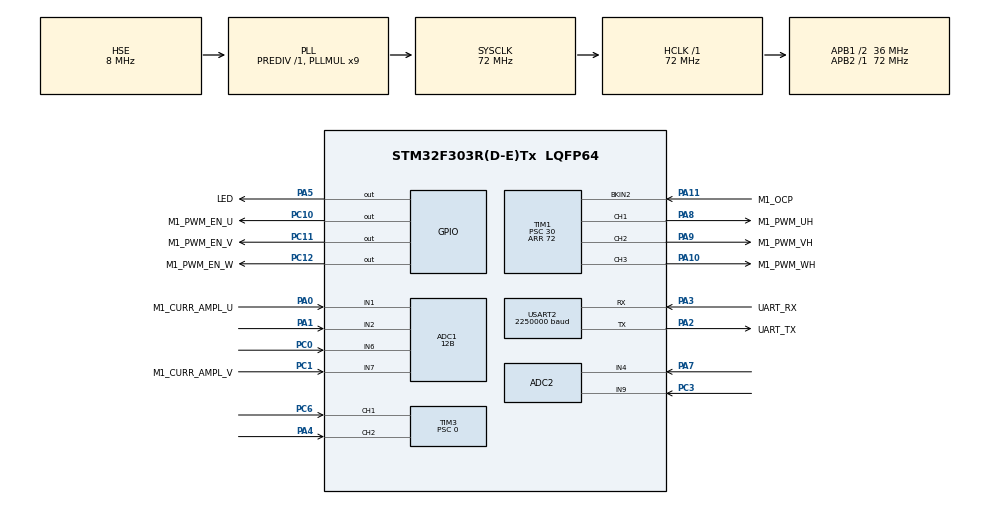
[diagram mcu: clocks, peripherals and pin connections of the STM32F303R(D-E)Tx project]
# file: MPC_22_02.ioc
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Dma.ADC2.2.Priority=DMA_PRIORITY_LOW
ADC1.LowPowerAutoWait=DISABLE
PC10.GPIO_PuPd=GPIO_PULLDOWN
TIM1.OCIdleState_1=TIM_OCIDLESTATE_RESET
TIM1.OCIdleState_2=TIM_OCIDLESTATE_RESET
Dma.USART2_TX.3.MemInc=DMA_MINC_ENABLE
PA10.GPIO_PuPd=GPIO_PULLDOWN
TIM1.Break2State=TIM_BREAK2_ENABLE
TIM1.OCIdleState_3=TIM_OCIDLESTATE_RESET
PC12.Signal=GPIO_Output
TIM1.OCIdleState_4=TIM_OCIDLESTATE_RESET
PA14.GPIO_Label=TCK
PA3.GPIO_PuPd=GPIO_NOPULL
ADC1.SamplingTimeOPAMP-4\#ChannelRegularConversion=ADC_SAMPLETIME_61CYCLES_5
PA3.GPIO_Speed=GPIO_SPEED_FREQ_LOW
TIM1.OCMode_PWM-PWM\ Generation3\ CH3=TIM_OCMODE_PWM1
Dma.USART2_RX.0.PeriphDataAlignment=DMA_PDATAALIGN_BYTE
RCC.APB2TimFreq_Value=72000000
ADC1.Channel-2\#ChannelRegularConversion=ADC_CHANNEL_7
Dma.ADC1.1.PeriphDataAlignment=DMA_PDATAALIGN_WORD
TIM1.AutomaticOutput=TIM_AUTOMATICOUTPUT_DISABLE
RCC.Usart2ClockSelection=RCC_USART2CLKSOURCE_SYSCLK
PC3.Signal=ADCx_IN9
ADC1.Offset-3\#ChannelRegularConversion=0
ADC1.ScanConvMode=ADC_SCAN_ENABLE
TIM1.LockLevel=TIM_LOCKLEVEL_1
USART2.OverSampling=UART_OVERSAMPLING_8
TIM1.Break2Polarity=TIM_BREAK2POLARITY_LOW
TIM1.Channel-PWM\ Generation1\ CH1=TIM_CHANNEL_1
PA0.Mode=IN1-Single-Ended
PC11.GPIO_Speed=GPIO_SPEED_FREQ_HIGH
PA8.Signal=S_TIM1_CH1
Dma.ADC2.2.Instance=DMA2_Channel1
VP_TIM1_VS_ClockSourceINT.Mode=Internal
PA0.Signal=ADC1_IN1
Mcu.Package=LQFP64
ADC1.EnableInjectedConversion=DISABLE
Dma.ADC2.2.PeriphInc=DMA_PINC_DISABLE
ADC2.Channel-20\#ChannelRegularConversion=ADC_CHANNEL_9
TIM1.OCFastMode_PWM-PWM\ Generation3\ CH3=TIM_OCFAST_ENABLE
PA10.Signal=S_TIM1_CH3
PC6.GPIO_PuPd=GPIO_PULLUP
SH.ADCx_IN9.0=ADC2_IN9,IN9-Single-Ended
Dma.ADC2.2.MemInc=DMA_MINC_ENABLE
RCC.APB1TimFreq_Value=72000000
TIM1.Period=72
PC12.GPIO_PuPd=GPIO_PULLDOWN
Dma.ADC2.2.PeriphDataAlignment=DMA_PDATAALIGN_WORD
TIM1.OCFastMode_PWM-PWM\ Generation4\ No\ Output=TIM_OCFAST_ENABLE
PA8.GPIO_Speed=GPIO_SPEED_FREQ_HIGH
ADC1.EOCSelection=ADC_EOC_SINGLE_CONV
PF1-OSC_OUT.Signal=RCC_OSC_OUT
ADC1.Rank-4\#ChannelRegularConversion=4
PA2.GPIO_Mode=GPIO_MODE_AF_PP
NVIC.DMA1_Channel6_IRQn=true\:1\:0\:true\:true\:true\:2\:true\:true
TIM1.OCPolarity_1=TIM_OCPOLARITY_HIGH
TIM1.OCPolarity_3=TIM_OCPOLARITY_HIGH
TIM1.OCPolarity_2=TIM_OCPOLARITY_HIGH
TIM1.OCPolarity_4=TIM_OCPOLARITY_HIGH
TIM3.AutoReloadPreload=TIM_AUTORELOAD_PRELOAD_ENABLE
SH.ADCx_IN6.0=ADC1_IN6,IN6-Single-Ended
TIM1.CounterMode=TIM_COUNTERMODE_CENTERALIGNED1
PA9.GPIO_Label=M1_PWM_VH
PC6.Signal=S_TIM3_CH1
Dma.USART2_RX.0.Direction=DMA_PERIPH_TO_MEMORY
PA11.GPIO_Label=M1_OCP
Dma.USART2_TX.3.PeriphInc=DMA_PINC_DISABLE
ADC1.ExternalTrigConvEdge=ADC_EXTERNALTRIGCONVEDGE_NONE
PC0.Signal=ADCx_IN6
RCC.APB1CLKDivider=RCC_HCLK_DIV2
USART2.BaudRate=2250000
TIM1.AutoReloadPreload=TIM_AUTORELOAD_PRELOAD_ENABLE
PA3.Mode=Asynchronous
TIM1.BreakFilter=0
PA8.GPIO_Label=M1_PWM_UH
ADC2.OffsetNumber-19\#ChannelRegularConversion=ADC_OFFSET_NONE
ADC2.ContinuousConvMode=ENABLE
SH.ADCx_IN7.0=ADC1_IN7,IN7-Single-Ended
PA9.Signal=S_TIM1_CH2
TIM1.Channel-PWM\ Generation2\ CH2=TIM_CHANNEL_2
USART2.OneBitSampling=UART_ONE_BIT_SAMPLE_ENABLE
ADC1.Offset-2\#ChannelRegularConversion=0
PA5.Signal=GPIO_Output
RCC.TIM8Selection=RCC_TIM8CLK_PLLCLK
NVIC.TIM1_BRK_TIM15_IRQn=true\:0\:0\:false\:false\:true\:true\:true
TIM1.TIM_MasterOutputTrigger=TIM_TRGO_OC4REF
PA1.Mode=IN2-Single-Ended
PA4.GPIO_ModeDefaultPP=GPIO_MODE_AF_PP
Dma.USART2_TX.3.Mode=DMA_NORMAL
Dma.ADC2.2.Direction=DMA_PERIPH_TO_MEMORY
ADC2.Rank-19\#ChannelRegularConversion=1
ADC1.DMAContinuousRequests=DISABLE
PA13.Mode=Serial_Wire
TIM1.Channel-PWM\ Generation4\ No\ Output=TIM_CHANNEL_4
Dma.USART2_RX.0.MemInc=DMA_MINC_ENABLE
ADC1.ExternalTrigConv=ADC_SOFTWARE_START
NVIC.TIM1_CC_IRQn=true\:0\:0\:false\:true\:true\:1\:true\:true
Dma.ADC2.2.Mode=DMA_CIRCULAR
ADC1.SamplingTime-1\#ChannelRegularConversion=ADC_SAMPLETIME_1CYCLE_5
PA4.Signal=S_TIM3_CH2
ADC1.master=1
ADC2.Channel-19\#ChannelRegularConversion=ADC_CHANNEL_4
ADC2.NbrOfConversionFlag=1
PA5.GPIO_Label=LED
PC12.GPIO_Label=M1_PWM_EN_W
ADC1.Rank-1\#ChannelRegularConversion=1
PA11.Signal=TIM1_BKIN2
ProjectManager.HeapSize=0x200
Dma.USART2_TX.3.Priority=DMA_PRIORITY_LOW
NVIC.PriorityGroup=NVIC_PRIORITYGROUP_3
ADC1.EnableRegularConversion=ENABLE
TIM1.Channel-PWM\ Generation3\ CH3=TIM_CHANNEL_3
PF0-OSC_IN.Signal=RCC_OSC_IN
PC1.Signal=ADCx_IN7
RCC.TIM2Selection=RCC_TIM2CLK_PLLCLK
Mcu.Family=STM32F3
PA2.GPIO_PuPd=GPIO_NOPULL
RCC.CortexFreq_Value=72000000
Dma.ADC1.1.MemDataAlignment=DMA_MDATAALIGN_WORD
ADC1.Overrun=ADC_OVR_DATA_OVERWRITTEN
ADC1.ContinuousConvMode=ENABLE
TIM1.RepetitionCounter=0
PC10.Signal=GPIO_Output
RCC.SYSCLKSourceVirtual=RCC_SYSCLKSOURCE_PLLCLK
ADC1.OffsetNumber-4\#ChannelRegularConversion=ADC_OFFSET_NONE
PA0.GPIO_Label=M1_CURR_AMPL_U
TIM3.EncoderMode=TIM_ENCODERMODE_TI1
PA2.GPIO_Speed=GPIO_SPEED_FREQ_LOW
PA11.Mode=Activate-Break-Input-2
PC10.GPIO_Speed=GPIO_SPEED_FREQ_HIGH
PA11.GPIO_PuPd=GPIO_PULLUP
Dma.USART2_TX.3.Direction=DMA_MEMORY_TO_PERIPH
TIM1.Pulse-PWM\ Generation1\ CH1=0
TIM1.OCFastMode_PWM-PWM\ Generation1\ CH1=TIM_OCFAST_ENABLE
ProjectManager.StackSize=0x400
PC11.GPIO_PuPd=GPIO_PULLDOWN
TIM1.Prescaler=30
Dma.USART2_RX.0.Priority=DMA_PRIORITY_LOW
Dma.ADC1.1.Instance=DMA1_Channel1
PC6.GPIO_ModeDefaultPP=GPIO_MODE_AF_PP
ADC1.Channel-3\#ChannelRegularConversion=ADC_CHANNEL_6
RCC.HCLKFreq_Value=72000000
ADC1.Resolution=ADC_RESOLUTION_12B
ADC1.Offset-1\#ChannelRegularConversion=0
TIM3.Period=599
ADC2.Offset-20\#ChannelRegularConversion=0
RCC.AHBFreq_Value=72000000
RCC.HSE_VALUE=8000000
PA4.GPIO_PuPd=GPIO_PULLUP
USART2.VirtualMode-Asynchronous=VM_ASYNC
RCC.PLLMUL=RCC_PLL_MUL9
ADC1.SamplingTime-4\#ChannelRegularConversion=ADC_SAMPLETIME_1CYCLE_5
ADC1.Rank-2\#ChannelRegularConversion=2
Dma.USART2_RX.0.MemDataAlignment=DMA_MDATAALIGN_BYTE
ADC2.SamplingTime-20\#ChannelRegularConversion=ADC_SAMPLETIME_1CYCLE_5
PA14.Mode=Serial_Wire
TIM3.Prescaler=0
PC11.GPIO_Label=M1_PWM_EN_V
PA10.GPIO_Label=M1_PWM_WH
Dma.USART2_RX.0.Instance=DMA1_Channel6
Dma.ADC1.1.Priority=DMA_PRIORITY_LOW
Dma.ADC1.1.Mode=DMA_CIRCULAR
ADC2.Offset-19\#ChannelRegularConversion=0
SH.S_TIM3_CH1.0=TIM3_CH1,Encoder_Interface
Dma.USART2_RX.0.PeriphInc=DMA_PINC_DISABLE
TIM1.Pulse-PWM\ Generation2\ CH2=0
Dma.ADC1.1.Direction=DMA_PERIPH_TO_MEMORY
Dma.ADC2.2.MemDataAlignment=DMA_MDATAALIGN_WORD
ADC2.OffsetNumber-20\#ChannelRegularConversion=ADC_OFFSET_NONE
PA2.GPIO_Label=UART_TX
Dma.ADC1.1.MemInc=DMA_MINC_ENABLE
ADC1.OffsetNumber-1\#ChannelRegularConversion=ADC_OFFSET_NONE
USART2.WordLength=WORDLENGTH_8B
PA10.GPIO_Speed=GPIO_SPEED_FREQ_HIGH
ADC2.NbrOfConversion=2
TIM1.BreakState=TIM_BREAK_DISABLE
Dma.Request2=ADC2
Dma.Request1=ADC1
Dma.Request3=USART2_TX
PF1-OSC_OUT.Mode=HSE-External-Oscillator
Dma.Request0=USART2_RX
PA3.Signal=USART2_RX
RCC.PLLSourceVirtual=RCC_PLLSOURCE_HSE
Dma.USART2_TX.3.MemDataAlignment=DMA_MDATAALIGN_BYTE
TIM1.OCMode_PWM-PWM\ Generation4\ No\ Output=TIM_OCMODE_PWM2
TIM1.OffStateIDLEMode=TIM_OSSI_ENABLE
PA7.Mode=IN4-Single-Ended
ADC1.Channel-4\#ChannelRegularConversion=ADC_CHANNEL_2
USART2.DMADisableonRxErrorParam=ADVFEATURE_DMA_DISABLEONRXERROR
PC10.GPIO_Label=M1_PWM_EN_U
Dma.USART2_TX.3.Instance=DMA1_Channel7
PC11.Signal=GPIO_Output
ADC1.OffsetNumber-3\#ChannelRegularConversion=ADC_OFFSET_NONE
ADC1.DiscontinuousConvMode=DISABLE
PA9.GPIO_PuPd=GPIO_PULLDOWN
ADC1.SamplingTime-2\#ChannelRegularConversion=ADC_SAMPLETIME_1CYCLE_5
TIM1.ClockDivision=TIM_CLOCKDIVISION_DIV1
Dma.USART2_RX.0.Mode=DMA_CIRCULAR
TIM1.ClearInputSource=TIM_CLEARINPUTSOURCE_NONE
TIM1.OCFastMode_PWM-PWM\ Generation2\ CH2=TIM_OCFAST_ENABLE
PA13.Signal=SYS_JTMS-SWDIO
TIM1.Pulse-PWM\ Generation3\ CH3=0
SH.S_TIM1_CH1.0=TIM1_CH1,PWM Generation1 CH1
ProjectManager.TargetToolchain=STM32CubeIDE
PA3.GPIO_Mode=GPIO_MODE_AF_PP
ADC1.Channel-1\#ChannelRegularConversion=ADC_CHANNEL_1
ADC1.EnableAnalogWatchDog3=false
ADC1.EnableAnalogWatchDog2=false
ADC1.EnableAnalogWatchDog1=false
Dma.USART2_TX.3.PeriphDataAlignment=DMA_PDATAALIGN_BYTE
RCC.USBFreq_Value=72000000
RCC.LSE_VALUE=32768
PA1.Signal=ADC1_IN2
ADC1.Offset-4\#ChannelRegularConversion=0
PF0-OSC_IN.Mode=HSE-External-Oscillator
TIM3.IC2Polarity=TIM_ICPOLARITY_FALLING
ADC2.SamplingTime-19\#ChannelRegularConversion=ADC_SAMPLETIME_1CYCLE_5
SH.S_TIM3_CH2.0=TIM3_CH2,Encoder_Interface
board=custom
VP_TIM1_VS_no_output4.Mode=PWM Generation4 No Output
TIM1.Pulse-PWM\ Generation4\ No\ Output=72
RCC.APB2Freq_Value=72000000
SH.S_TIM1_CH2.0=TIM1_CH2,PWM Generation2 CH2
PC1.GPIO_Label=M1_CURR_AMPL_V
ADC2.Rank-20\#ChannelRegularConversion=2
Dma.ADC1.1.PeriphInc=DMA_PINC_DISABLE
TIM1.OffStateRunMode=TIM_OSSR_ENABLE
TIM1.BreakPolarity=TIM_BREAKPOLARITY_HIGH
ADC1.NbrOfConversion=4
ADC1.OffsetNumber-2\#ChannelRegularConversion=ADC_OFFSET_NONE
Mcu.Name=STM32F303R(D-E)Tx
TIM1.OCMode_PWM-PWM\ Generation1\ CH1=TIM_OCMODE_PWM1
PA13.GPIO_Label=TMS
PA2.Signal=USART2_TX
RCC.SYSCLKFreq_VALUE=72000000
TIM1.TIM_MasterOutputTrigger2=TIM_TRGO2_UPDATE
ADC1.SamplingTime-3\#ChannelRegularConversion=ADC_SAMPLETIME_1CYCLE_5
ADC1.Rank-3\#ChannelRegularConversion=3
TIM1.Break2Filter=3
TIM3.IC1Polarity=TIM_ICPOLARITY_FALLING
PA14.Signal=SYS_JTCK-SWCLK
SH.S_TIM1_CH3.0=TIM1_CH3,PWM Generation3 CH3
RCC.HSI_VALUE=8000000
PA8.GPIO_PuPd=GPIO_PULLDOWN
PA5.GPIO_Speed=GPIO_SPEED_FREQ_HIGH
ADC1.NbrOfConversionFlag=1
TIM1.OCMode_PWM-PWM\ Generation2\ CH2=TIM_OCMODE_PWM1
PA2.Mode=Asynchronous
PA9.GPIO_Speed=GPIO_SPEED_FREQ_HIGH
TIM3.TIM_MasterOutputTrigger=TIM_TRGO_RESET
ADC1.DataAlign=ADC_DATAALIGN_RIGHT
RCC.APB1Freq_Value=36000000
PC12.GPIO_Speed=GPIO_SPEED_FREQ_HIGH
TIM1.TIM_MasterSlaveMode=TIM_MASTERSLAVEMODE_DISABLE
PA3.GPIO_Label=UART_RX
PA7.Signal=ADC2_IN4

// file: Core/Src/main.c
/* USER CODE BEGIN Header */
/**
  ******************************************************************************
  * @file           : main.c
  * @brief          : Main program body
  ******************************************************************************
  * @attention
  *
  * <h2><center>&copy; Copyright (c) 2022 STMicroelectronics.
  * All rights reserved.</center></h2>
  *
  * This software component is licensed by ST under BSD 3-Clause license,
  * the "License"; You may not use this file except in compliance with the
  * License. You may obtain a copy of the License at:
  *                        opensource.org/licenses/BSD-3-Clause
  *
  ******************************************************************************
  */
/* USER CODE END Header */
#include "main.h"

/* USER CODE BEGIN PD */
void receiveUART();
void initModelPredictiveControl();
/* USER CODE END PD */

ADC_HandleTypeDef hadc1;
ADC_HandleTypeDef hadc2;
DMA_HandleTypeDef hdma_adc1;
DMA_HandleTypeDef hdma_adc2;

TIM_HandleTypeDef htim1;
TIM_HandleTypeDef htim3;

UART_HandleTypeDef huart2;
DMA_HandleTypeDef hdma_usart2_rx;
DMA_HandleTypeDef hdma_usart2_tx;

void SystemClock_Config(void);
static void MX_GPIO_Init(void);
static void MX_DMA_Init(void);
static void MX_ADC1_Init(void);
static void MX_TIM1_Init(void);
static void MX_USART2_UART_Init(void);
static void MX_ADC2_Init(void);
static void MX_TIM3_Init(void);
static void MX_NVIC_Init(void);

int main(void)
{

  /* MCU Configuration--------------------------------------------------------*/

  /* Reset of all peripherals, Initializes the Flash interface and the Systick. */
  HAL_Init();

  /* Configure the system clock */
  SystemClock_Config();

  /* Initialize all configured peripherals */
  MX_GPIO_Init();
  MX_DMA_Init();
  MX_ADC1_Init();
  MX_TIM1_Init();
  MX_USART2_UART_Init();
  MX_ADC2_Init();
  MX_TIM3_Init();

  /* Initialize interrupts */
  MX_NVIC_Init();
  /* USER CODE BEGIN 2 */
	HAL_TIM_Encoder_Start(&htim3, TIM_CHANNEL_ALL);

	initModelPredictiveControl();

	// Calibrate ADCs
		HAL_ADCEx_Calibration_Start(&hadc1, ADC_SINGLE_ENDED);

		// Enable MOSFET drivers
		HAL_GPIO_WritePin(GPIOC, GPIO_PIN_10, 1);
		HAL_GPIO_WritePin(GPIOC, GPIO_PIN_11, 1);
		HAL_GPIO_WritePin(GPIOC, GPIO_PIN_12, 1);

	//	 Start timers
		HAL_TIM_PWM_Start_IT(&htim1, TIM_CHANNEL_4);
		HAL_TIM_PWM_Start(&htim1, TIM_CHANNEL_1);
		HAL_TIM_PWM_Start(&htim1, TIM_CHANNEL_2);
		HAL_TIM_PWM_Start(&htim1, TIM_CHANNEL_3);

		receiveUART();

  /* USER CODE END 2 */

  /* Infinite loop */
  while (1)
  {

  }
}

void SystemClock_Config(void)
{
  RCC_OscInitTypeDef RCC_OscInitStruct = {0};
  RCC_ClkInitTypeDef RCC_ClkInitStruct = {0};
  RCC_PeriphCLKInitTypeDef PeriphClkInit = {0};

  /** Initializes the RCC Oscillators according to the specified parameters
  * in the RCC_OscInitTypeDef structure.
  */
  RCC_OscInitStruct.OscillatorType = RCC_OSCILLATORTYPE_HSE;
  RCC_OscInitStruct.HSEState = RCC_HSE_ON;
  RCC_OscInitStruct.HSIState = RCC_HSI_ON;
  RCC_OscInitStruct.PLL.PLLState = RCC_PLL_ON;
  RCC_OscInitStruct.PLL.PLLSource = RCC_PLLSOURCE_HSE;
  RCC_OscInitStruct.PLL.PLLMUL = RCC_PLL_MUL9;
  RCC_OscInitStruct.PLL.PREDIV = RCC_PREDIV_DIV1;
  if (HAL_RCC_OscConfig(&RCC_OscInitStruct) != HAL_OK)
  {
    Error_Handler();
  }
  /** Initializes the CPU, AHB and APB buses clocks
  */
  RCC_ClkInitStruct.ClockType = RCC_CLOCKTYPE_HCLK|RCC_CLOCKTYPE_SYSCLK
                              |RCC_CLOCKTYPE_PCLK1|RCC_CLOCKTYPE_PCLK2;
  RCC_ClkInitStruct.SYSCLKSource = RCC_SYSCLKSOURCE_PLLCLK;
  RCC_ClkInitStruct.AHBCLKDivider = RCC_SYSCLK_DIV1;
  RCC_ClkInitStruct.APB1CLKDivider = RCC_HCLK_DIV2;
  RCC_ClkInitStruct.APB2CLKDivider = RCC_HCLK_DIV1;

  if (HAL_RCC_ClockConfig(&RCC_ClkInitStruct, FLASH_LATENCY_2) != HAL_OK)
  {
    Error_Handler();
  }
  PeriphClkInit.PeriphClockSelection = RCC_PERIPHCLK_USART2|RCC_PERIPHCLK_TIM1
                              |RCC_PERIPHCLK_ADC12|RCC_PERIPHCLK_TIM34;
  PeriphClkInit.Usart2ClockSelection = RCC_USART2CLKSOURCE_SYSCLK;
  PeriphClkInit.Adc12ClockSelection = RCC_ADC12PLLCLK_DIV1;
  PeriphClkInit.Tim1ClockSelection = RCC_TIM1CLK_HCLK;
  PeriphClkInit.Tim34ClockSelection = RCC_TIM34CLK_HCLK;
  if (HAL_RCCEx_PeriphCLKConfig(&PeriphClkInit) != HAL_OK)
  {
    Error_Handler();
  }
}

/**
  * @brief NVIC Configuration.
  * @retval None
  */
static void MX_NVIC_Init(void)
{
  /* TIM1_CC_IRQn interrupt configuration */
  HAL_NVIC_SetPriority(TIM1_CC_IRQn, 0, 0);
  HAL_NVIC_EnableIRQ(TIM1_CC_IRQn);
  /* DMA1_Channel6_IRQn interrupt configuration */
  HAL_NVIC_SetPriority(DMA1_Channel6_IRQn, 1, 0);
  HAL_NVIC_EnableIRQ(DMA1_Channel6_IRQn);
}

static void MX_ADC1_Init(void)
{

  ADC_MultiModeTypeDef multimode = {0};
  ADC_ChannelConfTypeDef sConfig = {0};

  /** Common config
  */
  hadc1.Instance = ADC1;
  hadc1.Init.ClockPrescaler = ADC_CLOCK_ASYNC_DIV1;
  hadc1.Init.Resolution = ADC_RESOLUTION_12B;
  hadc1.Init.ScanConvMode = ADC_SCAN_ENABLE;
  hadc1.Init.ContinuousConvMode = ENABLE;
  hadc1.Init.DiscontinuousConvMode = DISABLE;
  hadc1.Init.ExternalTrigConvEdge = ADC_EXTERNALTRIGCONVEDGE_NONE;
  hadc1.Init.ExternalTrigConv = ADC_SOFTWARE_START;
  hadc1.Init.DataAlign = ADC_DATAALIGN_RIGHT;
  hadc1.Init.NbrOfConversion = 4;
  hadc1.Init.DMAContinuousRequests = DISABLE;
  hadc1.Init.EOCSelection = ADC_EOC_SINGLE_CONV;
  hadc1.Init.LowPowerAutoWait = DISABLE;
  hadc1.Init.Overrun = ADC_OVR_DATA_OVERWRITTEN;
  if (HAL_ADC_Init(&hadc1) != HAL_OK)
  {
    Error_Handler();
  }
  /** Configure the ADC multi-mode
  */
  multimode.Mode = ADC_MODE_INDEPENDENT;
  if (HAL_ADCEx_MultiModeConfigChannel(&hadc1, &multimode) != HAL_OK)
  {
    Error_Handler();
  }
  /** Configure Regular Channel
  */
  sConfig.Channel = ADC_CHANNEL_1;
  sConfig.Rank = ADC_REGULAR_RANK_1;
  sConfig.SingleDiff = ADC_SINGLE_ENDED;
  sConfig.SamplingTime = ADC_SAMPLETIME_1CYCLE_5;
  sConfig.OffsetNumber = ADC_OFFSET_NONE;
  sConfig.Offset = 0;
  if (HAL_ADC_ConfigChannel(&hadc1, &sConfig) != HAL_OK)
  {
    Error_Handler();
  }
  /** Configure Regular Channel
  */
  sConfig.Channel = ADC_CHANNEL_7;
  sConfig.Rank = ADC_REGULAR_RANK_2;
  if (HAL_ADC_ConfigChannel(&hadc1, &sConfig) != HAL_OK)
  {
    Error_Handler();
  }
  /** Configure Regular Channel
  */
  sConfig.Channel = ADC_CHANNEL_6;
  sConfig.Rank = ADC_REGULAR_RANK_3;
  if (HAL_ADC_ConfigChannel(&hadc1, &sConfig) != HAL_OK)
  {
    Error_Handler();
  }
  /** Configure Regular Channel
  */
  sConfig.Channel = ADC_CHANNEL_2;
  sConfig.Rank = ADC_REGULAR_RANK_4;
  if (HAL_ADC_ConfigChannel(&hadc1, &sConfig) != HAL_OK)
  {
    Error_Handler();
  }

}

static void MX_ADC2_Init(void)
{

  ADC_ChannelConfTypeDef sConfig = {0};

  /** Common config
  */
  hadc2.Instance = ADC2;
  hadc2.Init.ClockPrescaler = ADC_CLOCK_ASYNC_DIV1;
  hadc2.Init.Resolution = ADC_RESOLUTION_12B;
  hadc2.Init.ScanConvMode = ADC_SCAN_ENABLE;
  hadc2.Init.ContinuousConvMode = ENABLE;
  hadc2.Init.DiscontinuousConvMode = DISABLE;
  hadc2.Init.ExternalTrigConvEdge = ADC_EXTERNALTRIGCONVEDGE_NONE;
  hadc2.Init.ExternalTrigConv = ADC_SOFTWARE_START;
  hadc2.Init.DataAlign = ADC_DATAALIGN_RIGHT;
  hadc2.Init.NbrOfConversion = 2;
  hadc2.Init.DMAContinuousRequests = DISABLE;
  hadc2.Init.EOCSelection = ADC_EOC_SINGLE_CONV;
  hadc2.Init.LowPowerAutoWait = DISABLE;
  hadc2.Init.Overrun = ADC_OVR_DATA_OVERWRITTEN;
  if (HAL_ADC_Init(&hadc2) != HAL_OK)
  {
    Error_Handler();
  }
  /** Configure Regular Channel
  */
  sConfig.Channel = ADC_CHANNEL_4;
  sConfig.Rank = ADC_REGULAR_RANK_1;
  sConfig.SingleDiff = ADC_SINGLE_ENDED;
  sConfig.SamplingTime = ADC_SAMPLETIME_1CYCLE_5;
  sConfig.OffsetNumber = ADC_OFFSET_NONE;
  sConfig.Offset = 0;
  if (HAL_ADC_ConfigChannel(&hadc2, &sConfig) != HAL_OK)
  {
    Error_Handler();
  }
  /** Configure Regular Channel
  */
  sConfig.Channel = ADC_CHANNEL_9;
  sConfig.Rank = ADC_REGULAR_RANK_2;
  if (HAL_ADC_ConfigChannel(&hadc2, &sConfig) != HAL_OK)
  {
    Error_Handler();
  }

}

static void MX_TIM1_Init(void)
{

  TIM_ClockConfigTypeDef sClockSourceConfig = {0};
  TIM_MasterConfigTypeDef sMasterConfig = {0};
  TIM_OC_InitTypeDef sConfigOC = {0};
  TIM_BreakDeadTimeConfigTypeDef sBreakDeadTimeConfig = {0};

  htim1.Instance = TIM1;
  htim1.Init.Prescaler = 30;
  htim1.Init.CounterMode = TIM_COUNTERMODE_CENTERALIGNED1;
  htim1.Init.Period = 72;
  htim1.Init.ClockDivision = TIM_CLOCKDIVISION_DIV1;
  htim1.Init.RepetitionCounter = 0;
  htim1.Init.AutoReloadPreload = TIM_AUTORELOAD_PRELOAD_ENABLE;
  if (HAL_TIM_Base_Init(&htim1) != HAL_OK)
  {
    Error_Handler();
  }
  sClockSourceConfig.ClockSource = TIM_CLOCKSOURCE_INTERNAL;
  if (HAL_TIM_ConfigClockSource(&htim1, &sClockSourceConfig) != HAL_OK)
  {
    Error_Handler();
  }
  if (HAL_TIM_PWM_Init(&htim1) != HAL_OK)
  {
    Error_Handler();
  }
  sMasterConfig.MasterOutputTrigger = TIM_TRGO_OC4REF;
  sMasterConfig.MasterOutputTrigger2 = TIM_TRGO2_UPDATE;
  sMasterConfig.MasterSlaveMode = TIM_MASTERSLAVEMODE_DISABLE;
  if (HAL_TIMEx_MasterConfigSynchronization(&htim1, &sMasterConfig) != HAL_OK)
  {
    Error_Handler();
  }
  sConfigOC.OCMode = TIM_OCMODE_PWM1;
  sConfigOC.Pulse = 0;
  sConfigOC.OCPolarity = TIM_OCPOLARITY_HIGH;
  sConfigOC.OCNPolarity = TIM_OCNPOLARITY_HIGH;
  sConfigOC.OCFastMode = TIM_OCFAST_ENABLE;
  sConfigOC.OCIdleState = TIM_OCIDLESTATE_RESET;
  sConfigOC.OCNIdleState = TIM_OCNIDLESTATE_RESET;
  if (HAL_TIM_PWM_ConfigChannel(&htim1, &sConfigOC, TIM_CHANNEL_1) != HAL_OK)
  {
    Error_Handler();
  }
  if (HAL_TIM_PWM_ConfigChannel(&htim1, &sConfigOC, TIM_CHANNEL_2) != HAL_OK)
  {
    Error_Handler();
  }
  if (HAL_TIM_PWM_ConfigChannel(&htim1, &sConfigOC, TIM_CHANNEL_3) != HAL_OK)
  {
    Error_Handler();
  }
  sConfigOC.OCMode = TIM_OCMODE_PWM2;
  sConfigOC.Pulse = 72;
  if (HAL_TIM_PWM_ConfigChannel(&htim1, &sConfigOC, TIM_CHANNEL_4) != HAL_OK)
  {
    Error_Handler();
  }
  sBreakDeadTimeConfig.OffStateRunMode = TIM_OSSR_ENABLE;
  sBreakDeadTimeConfig.OffStateIDLEMode = TIM_OSSI_ENABLE;
  sBreakDeadTimeConfig.LockLevel = TIM_LOCKLEVEL_1;
  sBreakDeadTimeConfig.DeadTime = 0;
  sBreakDeadTimeConfig.BreakState = TIM_BREAK_DISABLE;
  sBreakDeadTimeConfig.BreakPolarity = TIM_BREAKPOLARITY_HIGH;
  sBreakDeadTimeConfig.BreakFilter = 0;
  sBreakDeadTimeConfig.Break2State = TIM_BREAK2_ENABLE;
  sBreakDeadTimeConfig.Break2Polarity = TIM_BREAK2POLARITY_LOW;
  sBreakDeadTimeConfig.Break2Filter = 3;
  sBreakDeadTimeConfig.AutomaticOutput = TIM_AUTOMATICOUTPUT_DISABLE;
  if (HAL_TIMEx_ConfigBreakDeadTime(&htim1, &sBreakDeadTimeConfig) != HAL_OK)
  {
    Error_Handler();
  }
  HAL_TIM_MspPostInit(&htim1);

}

static void MX_TIM3_Init(void)
{

  TIM_Encoder_InitTypeDef sConfig = {0};
  TIM_MasterConfigTypeDef sMasterConfig = {0};

  htim3.Instance = TIM3;
  htim3.Init.Prescaler = 0;
  htim3.Init.CounterMode = TIM_COUNTERMODE_UP;
  htim3.Init.Period = 299;
  htim3.Init.ClockDivision = TIM_CLOCKDIVISION_DIV1;
  htim3.Init.AutoReloadPreload = TIM_AUTORELOAD_PRELOAD_ENABLE;
  sConfig.EncoderMode = TIM_ENCODERMODE_TI1;
  sConfig.IC1Polarity = TIM_ICPOLARITY_FALLING;
  sConfig.IC1Selection = TIM_ICSELECTION_DIRECTTI;
  sConfig.IC1Prescaler = TIM_ICPSC_DIV1;
  sConfig.IC1Filter = 0;
  sConfig.IC2Polarity = TIM_ICPOLARITY_FALLING;
  sConfig.IC2Selection = TIM_ICSELECTION_DIRECTTI;
  sConfig.IC2Prescaler = TIM_ICPSC_DIV1;
  sConfig.IC2Filter = 0;
  if (HAL_TIM_Encoder_Init(&htim3, &sConfig) != HAL_OK)
  {
    Error_Handler();
  }
  sMasterConfig.MasterOutputTrigger = TIM_TRGO_RESET;
  sMasterConfig.MasterSlaveMode = TIM_MASTERSLAVEMODE_DISABLE;
  if (HAL_TIMEx_MasterConfigSynchronization(&htim3, &sMasterConfig) != HAL_OK)
  {
    Error_Handler();
  }

}

static void MX_USART2_UART_Init(void)
{

  huart2.Instance = USART2;
  huart2.Init.BaudRate = 2250000;
  huart2.Init.WordLength = UART_WORDLENGTH_8B;
  huart2.Init.StopBits = UART_STOPBITS_1;
  huart2.Init.Parity = UART_PARITY_NONE;
  huart2.Init.Mode = UART_MODE_TX_RX;
  huart2.Init.HwFlowCtl = UART_HWCONTROL_NONE;
  huart2.Init.OverSampling = UART_OVERSAMPLING_8;
  huart2.Init.OneBitSampling = UART_ONE_BIT_SAMPLE_ENABLE;
  huart2.AdvancedInit.AdvFeatureInit = UART_ADVFEATURE_DMADISABLEONERROR_INIT;
  huart2.AdvancedInit.DMADisableonRxError = UART_ADVFEATURE_DMA_DISABLEONRXERROR;
  if (HAL_UART_Init(&huart2) != HAL_OK)
  {
    Error_Handler();
  }

}

static void MX_DMA_Init(void)
{

  /* DMA controller clock enable */
  __HAL_RCC_DMA1_CLK_ENABLE();
  __HAL_RCC_DMA2_CLK_ENABLE();

}

static void MX_GPIO_Init(void)
{
  GPIO_InitTypeDef GPIO_InitStruct = {0};

  /* GPIO Ports Clock Enable */
  __HAL_RCC_GPIOF_CLK_ENABLE();
  __HAL_RCC_GPIOC_CLK_ENABLE();
  __HAL_RCC_GPIOA_CLK_ENABLE();

  /*Configure GPIO pin Output Level */
  HAL_GPIO_WritePin(GPIOA, GPIO_PIN_5, GPIO_PIN_RESET);

  /*Configure GPIO pin Output Level */
  HAL_GPIO_WritePin(GPIOC, M1_PWM_EN_U_Pin|M1_PWM_EN_V_Pin|M1_PWM_EN_W_Pin, GPIO_PIN_RESET);

  /*Configure GPIO pin : PA5 */
  GPIO_InitStruct.Pin = GPIO_PIN_5;
  GPIO_InitStruct.Mode = GPIO_MODE_OUTPUT_PP;
  GPIO_InitStruct.Pull = GPIO_NOPULL;
  GPIO_InitStruct.Speed = GPIO_SPEED_FREQ_HIGH;
  HAL_GPIO_Init(GPIOA, &GPIO_InitStruct);

  /*Configure GPIO pins : M1_PWM_EN_U_Pin M1_PWM_EN_V_Pin M1_PWM_EN_W_Pin */
  GPIO_InitStruct.Pin = M1_PWM_EN_U_Pin|M1_PWM_EN_V_Pin|M1_PWM_EN_W_Pin;
  GPIO_InitStruct.Mode = GPIO_MODE_OUTPUT_PP;
  GPIO_InitStruct.Pull = GPIO_PULLDOWN;
  GPIO_InitStruct.Speed = GPIO_SPEED_FREQ_HIGH;
  HAL_GPIO_Init(GPIOC, &GPIO_InitStruct);

}

void Error_Handler(void)
{
  __disable_irq();
  while (1)
  {
  }
}

/************************ (C) COPYRIGHT STMicroelectronics *****END OF FILE****/
